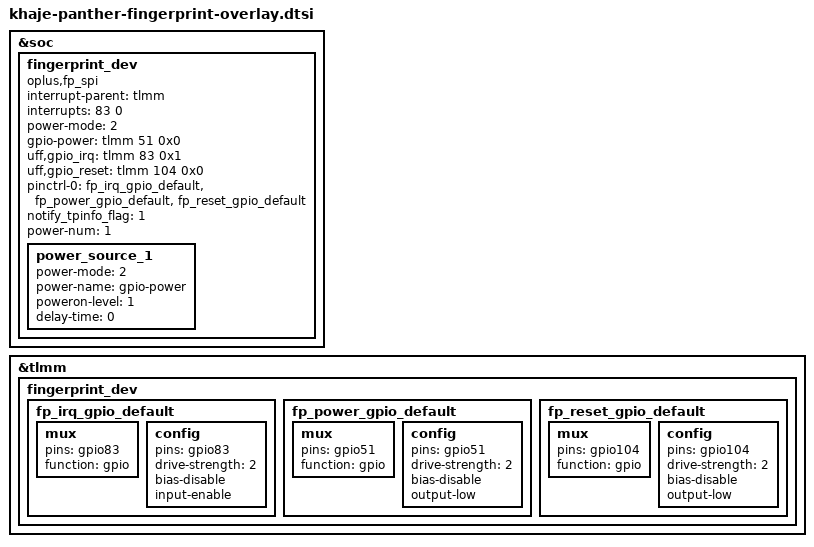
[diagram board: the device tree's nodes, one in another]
// SPDX-License-Identifier: GPL-2.0-only
/*
 * Copyright (C) 2018-2020 Oplus. All rights reserved.
 */

&soc {
	fingerprint_dev {
		status = "ok";
		compatible = "oplus,fp_spi";
		interrupt-parent = <&tlmm>;
		interrupts = <83 0>;
		power-mode = <2> ; /*please refer to the struct fp_power_mode_t in oppo_fp_commmon.n ,0: power mode not set, 1: ldo power, 2: gpio power, 3: auto power */
		gpio-power = <&tlmm 51 0x0>;
		uff,gpio_irq = <&tlmm 83 0x1>;
		uff,gpio_reset = <&tlmm 104 0x0>;
		pinctrl-names = "default";
		pinctrl-0 = <&fp_irq_gpio_default>,<&fp_power_gpio_default>,<&fp_reset_gpio_default>;
		notify_tpinfo_flag = <1>;
		power-num = <1>;
		power_source_1 {
			power-mode = <2>;    /* power mode: 1 -- ldo; 2 -- gpio */
			power-name = "gpio-power";
			poweron-level = <1>;
			delay-time = <0>;
		};
	};
};

&tlmm {
	fingerprint_dev{
		fp_irq_gpio_default: fp_irq_gpio_default {
			mux {
				pins = "gpio83";
				function = "gpio";
			};
			config {
				pins = "gpio83";
				drive-strength = <2>;
				bias-disable;
				input-enable;
			};
		};

		fp_power_gpio_default: fp_power_gpio_default {
			mux {
				pins = "gpio51";
				function = "gpio";
			};
			config {
				pins = "gpio51";
				drive-strength = <2>;
				bias-disable;
				output-low;
			};
		};

		fp_reset_gpio_default: fp_reset_gpio_default {
			mux {
				pins = "gpio104";
				function = "gpio";
			};
			config {
				pins = "gpio104";
				drive-strength = <2>;
				bias-disable;
				output-low;
			};
		};
	};
};

